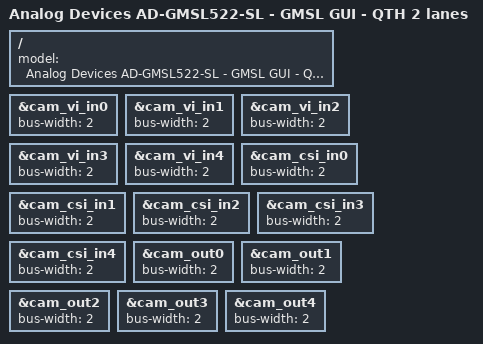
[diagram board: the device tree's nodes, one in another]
// SPDX-License-Identifier: GPL-2.0
/*
 * Copyright (C) 2025 Analog Devices Inc.
 */

/dts-v1/;

#include "tegra194-p3668-0001-gmsl522-revb.dts"

/ {
	model = "Analog Devices AD-GMSL522-SL - GMSL GUI - QTH 2 lanes";
};

#include "common/tegra194-gmsl522-reva-gmsl-generic.dtsi"

&cam_vi_in0 {
	bus-width = <2>;
};

&cam_vi_in1 {
	bus-width = <2>;
};

&cam_vi_in2 {
	bus-width = <2>;
};

&cam_vi_in3 {
	bus-width = <2>;
};

&cam_vi_in4 {
	bus-width = <2>;
};

&cam_csi_in0 {
	bus-width = <2>;
};

&cam_csi_in1 {
	bus-width = <2>;
};

&cam_csi_in2 {
	bus-width = <2>;
};

&cam_csi_in3 {
	bus-width = <2>;
};

&cam_csi_in4 {
	bus-width = <2>;
};

&cam_out0 {
	bus-width = <2>;
};

&cam_out1 {
	bus-width = <2>;
};

&cam_out2 {
	bus-width = <2>;
};

&cam_out3 {
	bus-width = <2>;
};

&cam_out4 {
	bus-width = <2>;
};
